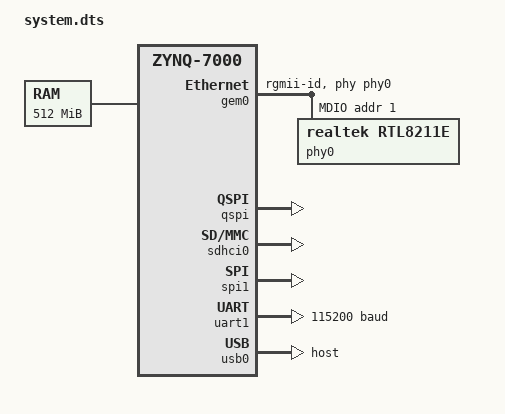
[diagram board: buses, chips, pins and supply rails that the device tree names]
/*
 * CAUTION: This file is automatically generated by Xilinx.
 * Version:  
 * Today is: Fri Apr  8 11:16:21 2016
*/


/dts-v1/;
/include/ "zynq-7000.dtsi"
/include/ "pl.dtsi"
/ {
	cpus {
		cpu@0 {
			operating-points = <666666 1000000 333333 1000000>;
		};
	};
	chosen {
		bootargs = "console=ttyPS0,115200 root=/dev/mmcblk0p2 rw earlyprintk rootfstype=ext4 rootwait devtmpfs.mount=0";
	};
	aliases {
		ethernet0 = &gem0;
		serial0 = &uart1;
		spi0 = &qspi;
		spi1 = &spi1;
	};
	memory {
		device_type = "memory";
		reg = <0x0 0x20000000>;
	};
};
&gem0 {
	local-mac-address = [00 0a 35 00 00 00];
	phy-mode = "rgmii-id";
	status = "okay";
	phy-handle = <&phy0>;
	xlnx,eth-mode = <0x1>;
	xlnx,has-mdio = <0x1>;
	xlnx,ptp-enet-clock = <0x69f6bcb>;
	ps7_ethernet_0_mdio: mdio {
		#address-cells = <1>;
		#size-cells = <0>;
		
		phy0: phy@1 {
			compatible = "realtek,RTL8211E";
			device_type = "ethernet-phy";
			reg = <1>;
		} ;
	};
};
&gpio0 {
	emio-gpio-width = <64>;
	gpio-mask-high = <0x0>;
	gpio-mask-low = <0x5600>;
};
&intc {
	num_cpus = <2>;
	num_interrupts = <96>;
};
&qspi {
	is-dual = <0>;
	num-cs = <1>;
	status = "okay";
};
&sdhci0 {
	status = "okay";
	xlnx,has-cd = <0x1>;
	xlnx,has-power = <0x0>;
	xlnx,has-wp = <0x1>;
};
&spi1 {
	is-decoded-cs = <0>;
	num-cs = <3>;
	status = "okay";
};
&uart1 {
	current-speed = <115200>;
	device_type = "serial";
	port-number = <0>;
	status = "okay";
};
&usb0 {
	dr_mode = "host";
	phy_type = "ulpi";
	status = "okay";
};
&clkc {
	fclk-enable = <0x1>;
	ps-clk-frequency = <33333333>;
};
